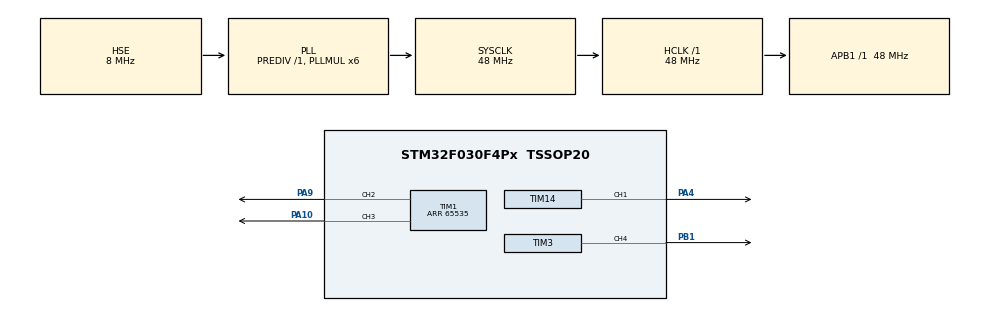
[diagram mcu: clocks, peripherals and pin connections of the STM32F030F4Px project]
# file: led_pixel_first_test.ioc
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Mcu.Family=STM32F0
Mcu.Name=STM32F030F4Px
Mcu.Package=TSSOP20
PA10.Signal=S_TIM1_CH3
PA13.Mode=Serial-WireDebug
PA13.Signal=SYS_SWDIO
PA14.Mode=Serial-WireDebug
PA14.Signal=SYS_SWCLK
PA4.Signal=S_TIM14_CH1
PA9.Signal=S_TIM1_CH2
PB1.Signal=S_TIM3_CH4
PF0-OSC_IN.Mode=HSE-External-Oscillator
PF0-OSC_IN.Signal=RCC_OSC_IN
PF1-OSC_OUT.Mode=HSE-External-Oscillator
PF1-OSC_OUT.Signal=RCC_OSC_OUT
ProjectManager.TargetToolchain=SW4STM32
RCC.AHBFreq_Value=48000000
RCC.APB1Freq_Value=48000000
RCC.APB1TimFreq_Value=48000000
RCC.HCLKFreq_Value=48000000
RCC.HSIState=RCC_HSI_ON
RCC.PLLMUL=RCC_PLL_MUL6
RCC.PLLSourceVirtual=RCC_PLLSOURCE_HSE
RCC.SYSCLKFreq_VALUE=48000000
RCC.SYSCLKSource=RCC_SYSCLKSOURCE_PLLCLK
SH.S_TIM14_CH1.0=TIM14_CH1,PWM Generation1 CH1
SH.S_TIM1_CH2.0=TIM1_CH2,PWM Generation2 CH2
SH.S_TIM1_CH3.0=TIM1_CH3,PWM Generation3 CH3
SH.S_TIM3_CH4.0=TIM3_CH4,PWM Generation4 CH4
TIM1.Channel-PWM\ Generation2\ CH2=TIM_CHANNEL_2
TIM1.Channel-PWM\ Generation3\ CH3=TIM_CHANNEL_3
TIM1.OCMode_PWM-PWM\ Generation2\ CH2=TIM_OCMODE_PWM1
TIM1.Period=65535
TIM14.Period=65535
TIM3.Channel-PWM\ Generation4\ CH4=TIM_CHANNEL_4
TIM3.OCPolarity_4=TIM_OCPOLARITY_HIGH
TIM3.Period=65535
VP_TIM14_VS_ClockSourceINT.Mode=Enable_Timer
VP_TIM3_VS_ClockSourceINT.Mode=Internal
board=led_pixel_first_test

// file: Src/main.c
/**
  ******************************************************************************
  * File Name          : main.c
  * Description        : Main program body
  ******************************************************************************
  *
  * COPYRIGHT(c) 2017 STMicroelectronics
  *
  * Redistribution and use in source and binary forms, with or without modification,
  * are permitted provided that the following conditions are met:
  *   1. Redistributions of source code must retain the above copyright notice,
  *      this list of conditions and the following disclaimer.
  *   2. Redistributions in binary form must reproduce the above copyright notice,
  *      this list of conditions and the following disclaimer in the documentation
  *      and/or other materials provided with the distribution.
  *   3. Neither the name of STMicroelectronics nor the names of its contributors
  *      may be used to endorse or promote products derived from this software
  *      without specific prior written permission.
  *
  * THIS SOFTWARE IS PROVIDED BY THE COPYRIGHT HOLDERS AND CONTRIBUTORS "AS IS"
  * AND ANY EXPRESS OR IMPLIED WARRANTIES, INCLUDING, BUT NOT LIMITED TO, THE
  * IMPLIED WARRANTIES OF MERCHANTABILITY AND FITNESS FOR A PARTICULAR PURPOSE ARE
  * DISCLAIMED. IN NO EVENT SHALL THE COPYRIGHT HOLDER OR CONTRIBUTORS BE LIABLE
  * FOR ANY DIRECT, INDIRECT, INCIDENTAL, SPECIAL, EXEMPLARY, OR CONSEQUENTIAL
  * DAMAGES (INCLUDING, BUT NOT LIMITED TO, PROCUREMENT OF SUBSTITUTE GOODS OR
  * SERVICES; LOSS OF USE, DATA, OR PROFITS; OR BUSINESS INTERRUPTION) HOWEVER
  * CAUSED AND ON ANY THEORY OF LIABILITY, WHETHER IN CONTRACT, STRICT LIABILITY,
  * OR TORT (INCLUDING NEGLIGENCE OR OTHERWISE) ARISING IN ANY WAY OUT OF THE USE
  * OF THIS SOFTWARE, EVEN IF ADVISED OF THE POSSIBILITY OF SUCH DAMAGE.
  *
  ******************************************************************************
  */
#include "stm32f0xx_hal.h"
#include <stdlib.h>

TIM_HandleTypeDef htim1;
TIM_HandleTypeDef htim3;
TIM_HandleTypeDef htim14;

/* USER CODE BEGIN PV */
/* Private variables ---------------------------------------------------------*/

/* USER CODE END PV */

void SystemClock_Config(void);
static void MX_GPIO_Init(void);
static void MX_TIM1_Init(void);
static void MX_TIM3_Init(void);
static void MX_TIM14_Init(void);

/* USER CODE BEGIN PFP */
/* Private function prototypes -----------------------------------------------*/

/* USER CODE END PFP */

int main(void)
{

  /* MCU Configuration---------------
   * -------------------------------------------*/

  /* Reset of all peripherals, Initializes the Flash interface and the Systick. */
  HAL_Init();

  /* dummy initialization of the random number generation */
  srand(12345678);

  /* Configure the system clock */
  SystemClock_Config();

  /* Initialize all configured peripherals */
  MX_GPIO_Init();

  MX_TIM1_Init();
  MX_TIM3_Init();
  MX_TIM14_Init();

  /* USER CODE BEGIN 2 */

  GPIOA->MODER &= ~GPIO_MODER_MODER4;
  GPIOA->MODER |= GPIO_MODER_MODER4_1;

  GPIOA->AFR[0] &= ~GPIO_AFRL_AFRL4;
  GPIOA->AFR[0] |= (0x4 << 16);

  GPIOA->MODER &= ~GPIO_MODER_MODER9;
  GPIOA->MODER |= GPIO_MODER_MODER9_1;

  GPIOA->AFR[1] &= ~GPIO_AFRH_AFRH1;
  GPIOA->AFR[1] |= (0x2 << 4);

  GPIOA->MODER &= ~GPIO_MODER_MODER10;
  GPIOA->MODER |= GPIO_MODER_MODER10_1;

  GPIOA->AFR[1] |= (0x2 << 8);

  GPIOB->MODER &= ~GPIO_MODER_MODER1;
  GPIOB->MODER |= GPIO_MODER_MODER1_1;

  GPIOB->AFR[0] |= (0x1 << 4);

  /* USER CODE END 2 */

  /* Infinite loop */
  while (1)
  {

  }

}

/** System Clock Configuration
*/
void SystemClock_Config(void)
{

  RCC_OscInitTypeDef RCC_OscInitStruct;
  RCC_ClkInitTypeDef RCC_ClkInitStruct;

  RCC_OscInitStruct.OscillatorType = RCC_OSCILLATORTYPE_HSE;
  RCC_OscInitStruct.HSEState = RCC_HSE_ON;
  RCC_OscInitStruct.PLL.PLLState = RCC_PLL_ON;
  RCC_OscInitStruct.PLL.PLLSource = RCC_PLLSOURCE_HSE;
  RCC_OscInitStruct.PLL.PLLMUL = RCC_PLL_MUL6;
  RCC_OscInitStruct.PLL.PREDIV = RCC_PREDIV_DIV1;
  HAL_RCC_OscConfig(&RCC_OscInitStruct);

  RCC_ClkInitStruct.ClockType = RCC_CLOCKTYPE_SYSCLK;
  RCC_ClkInitStruct.SYSCLKSource = RCC_SYSCLKSOURCE_PLLCLK;
  RCC_ClkInitStruct.AHBCLKDivider = RCC_SYSCLK_DIV1;
  RCC_ClkInitStruct.APB1CLKDivider = RCC_HCLK_DIV1;
  HAL_RCC_ClockConfig(&RCC_ClkInitStruct, FLASH_LATENCY_1);

  HAL_SYSTICK_Config(HAL_RCC_GetHCLKFreq()/1000);

  HAL_SYSTICK_CLKSourceConfig(SYSTICK_CLKSOURCE_HCLK);

  /* SysTick_IRQn interrupt configuration */
  HAL_NVIC_SetPriority(SysTick_IRQn, 0, 0);
}

/* TIM1 init function */
void MX_TIM1_Init(void)
{

  TIM_MasterConfigTypeDef sMasterConfig;
  TIM_BreakDeadTimeConfigTypeDef sBreakDeadTimeConfig;
  TIM_OC_InitTypeDef sConfigOC;

  htim1.Instance = TIM1;
  htim1.Init.Prescaler = 0;
  htim1.Init.CounterMode = TIM_COUNTERMODE_UP;
  htim1.Init.Period = 65535;
  htim1.Init.ClockDivision = TIM_CLOCKDIVISION_DIV1;
  htim1.Init.RepetitionCounter = 0;
  HAL_TIM_PWM_Init(&htim1);

  sMasterConfig.MasterOutputTrigger = TIM_TRGO_RESET;
  sMasterConfig.MasterSlaveMode = TIM_MASTERSLAVEMODE_DISABLE;
  HAL_TIMEx_MasterConfigSynchronization(&htim1, &sMasterConfig);

  sBreakDeadTimeConfig.OffStateRunMode = TIM_OSSR_DISABLE;
  sBreakDeadTimeConfig.OffStateIDLEMode = TIM_OSSI_DISABLE;
  sBreakDeadTimeConfig.LockLevel = TIM_LOCKLEVEL_OFF;
  sBreakDeadTimeConfig.DeadTime = 0;
  sBreakDeadTimeConfig.BreakState = TIM_BREAK_DISABLE;
  sBreakDeadTimeConfig.BreakPolarity = TIM_BREAKPOLARITY_HIGH;
  sBreakDeadTimeConfig.AutomaticOutput = TIM_AUTOMATICOUTPUT_DISABLE;
  HAL_TIMEx_ConfigBreakDeadTime(&htim1, &sBreakDeadTimeConfig);

  sConfigOC.OCMode = TIM_OCMODE_PWM1;
  sConfigOC.Pulse = 0;
  sConfigOC.OCPolarity = TIM_OCPOLARITY_HIGH;
  sConfigOC.OCNPolarity = TIM_OCNPOLARITY_HIGH;
  sConfigOC.OCFastMode = TIM_OCFAST_DISABLE;
  sConfigOC.OCIdleState = TIM_OCIDLESTATE_RESET;
  sConfigOC.OCNIdleState = TIM_OCNIDLESTATE_RESET;
  HAL_TIM_PWM_ConfigChannel(&htim1, &sConfigOC, TIM_CHANNEL_2);

  HAL_TIM_PWM_ConfigChannel(&htim1, &sConfigOC, TIM_CHANNEL_3);

  HAL_TIM_PWM_Start(&htim1, TIM_CHANNEL_2);
  HAL_TIM_PWM_Start(&htim1, TIM_CHANNEL_3);

}

/* TIM3 init function */
void MX_TIM3_Init(void)
{

  TIM_ClockConfigTypeDef sClockSourceConfig;
  TIM_MasterConfigTypeDef sMasterConfig;
  TIM_OC_InitTypeDef sConfigOC;

  htim3.Instance = TIM3;
  htim3.Init.Prescaler = 0;
  htim3.Init.CounterMode = TIM_COUNTERMODE_UP;
  htim3.Init.Period = 65535;
  htim3.Init.ClockDivision = TIM_CLOCKDIVISION_DIV1;
  HAL_TIM_Base_Init(&htim3);

  sClockSourceConfig.ClockSource = TIM_CLOCKSOURCE_INTERNAL;
  HAL_TIM_ConfigClockSource(&htim3, &sClockSourceConfig);

  HAL_TIM_PWM_Init(&htim3);

  sMasterConfig.MasterOutputTrigger = TIM_TRGO_RESET;
  sMasterConfig.MasterSlaveMode = TIM_MASTERSLAVEMODE_DISABLE;
  HAL_TIMEx_MasterConfigSynchronization(&htim3, &sMasterConfig);

  sConfigOC.OCMode = TIM_OCMODE_PWM1;
  sConfigOC.Pulse = 0;
  sConfigOC.OCPolarity = TIM_OCPOLARITY_HIGH;
  sConfigOC.OCFastMode = TIM_OCFAST_DISABLE;
  HAL_TIM_PWM_ConfigChannel(&htim3, &sConfigOC, TIM_CHANNEL_4);

  HAL_TIM_PWM_Start(&htim3, TIM_CHANNEL_4);

}

/* TIM14 init function */
void MX_TIM14_Init(void)
{

  TIM_OC_InitTypeDef sConfigOC;

  htim14.Instance = TIM14;
  htim14.Init.Prescaler = 0;
  htim14.Init.CounterMode = TIM_COUNTERMODE_UP;
  htim14.Init.Period = 65535;
  htim14.Init.ClockDivision = TIM_CLOCKDIVISION_DIV1;
  HAL_TIM_Base_Init(&htim14);

  HAL_TIM_PWM_Init(&htim14);

  sConfigOC.OCMode = TIM_OCMODE_PWM1;
  sConfigOC.Pulse = 0;
  sConfigOC.OCPolarity = TIM_OCPOLARITY_HIGH;
  sConfigOC.OCFastMode = TIM_OCFAST_DISABLE;
  HAL_TIM_PWM_ConfigChannel(&htim14, &sConfigOC, TIM_CHANNEL_1);

  HAL_TIM_PWM_Start(&htim14, TIM_CHANNEL_1);

}

/** Configure pins as
        * Analog
        * Input
        * Output
        * EVENT_OUT
        * EXTI
*/
void MX_GPIO_Init(void)
{

  /* GPIO Ports Clock Enable */
  __GPIOF_CLK_ENABLE();
  __GPIOA_CLK_ENABLE();
  __GPIOB_CLK_ENABLE();

}

/************************ (C) COPYRIGHT STMicroelectronics *****END OF FILE****/
